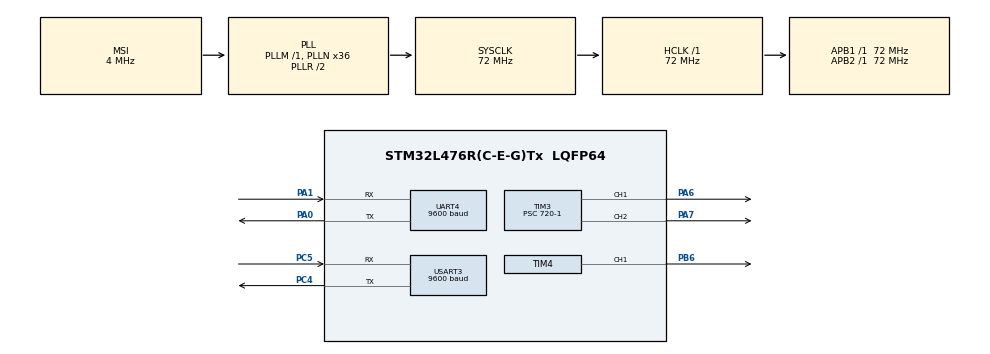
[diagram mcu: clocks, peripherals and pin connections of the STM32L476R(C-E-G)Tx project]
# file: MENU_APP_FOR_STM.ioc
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Mcu.Family=STM32L4
Mcu.Name=STM32L476R(C-E-G)Tx
Mcu.Package=LQFP64
NVIC.PriorityGroup=NVIC_PRIORITYGROUP_4
NVIC.TIM1_UP_TIM16_IRQn=true\:0\:0\:false\:false\:true\:true\:true\:true
NVIC.TIM3_IRQn=true\:0\:0\:false\:false\:true\:true\:true\:true
NVIC.TIM4_IRQn=true\:0\:0\:false\:false\:true\:true\:true\:true
NVIC.UART4_IRQn=true\:0\:0\:false\:false\:true\:true\:true\:true
NVIC.USART3_IRQn=true\:0\:0\:false\:false\:true\:true\:true\:true
PA0.Mode=Asynchronous
PA0.Signal=UART4_TX
PA1.Mode=Asynchronous
PA1.Signal=UART4_RX
PA6.Signal=S_TIM3_CH1
PA7.Signal=S_TIM3_CH2
PB6.Signal=S_TIM4_CH1
PC4.Mode=Asynchronous
PC4.Signal=USART3_TX
PC5.Mode=Asynchronous
PC5.Signal=USART3_RX
ProjectManager.HeapSize=0x200
ProjectManager.StackSize=0x400
ProjectManager.TargetToolchain=STM32CubeIDE
RCC.AHBFreq_Value=72000000
RCC.APB1Freq_Value=72000000
RCC.APB1TimFreq_Value=72000000
RCC.APB2Freq_Value=72000000
RCC.APB2TimFreq_Value=72000000
RCC.CortexFreq_Value=72000000
RCC.HCLKFreq_Value=72000000
RCC.HSE_VALUE=8000000
RCC.HSI_VALUE=16000000
RCC.LSE_VALUE=32768
RCC.MSI_VALUE=4000000
RCC.PLLN=36
RCC.SYSCLKFreq_VALUE=72000000
RCC.SYSCLKSource=RCC_SYSCLKSOURCE_PLLCLK
RCC.VCOOutputFreq_Value=144000000
SH.S_TIM3_CH1.0=TIM3_CH1,PWM Generation1 CH1
SH.S_TIM3_CH2.0=TIM3_CH2,PWM Generation2 CH2
SH.S_TIM4_CH1.0=TIM4_CH1,PWM Generation1 CH1
TIM16.Period=100-1
TIM16.Prescaler=720-1
TIM3.Channel-PWM\ Generation1\ CH1=TIM_CHANNEL_1
TIM3.Channel-PWM\ Generation2\ CH2=TIM_CHANNEL_2
TIM3.Period=200-1
TIM3.Prescaler=720-1
TIM4.Channel-PWM\ Generation1\ CH1=TIM_CHANNEL_1
TIM4.Period=200-1
TIM4.Prescaler=720-1
UART4.BaudRate=9600
USART3.BaudRate=9600
USART3.VirtualMode-Asynchronous=VM_ASYNC
VP_TIM16_VS_ClockSourceINT.Mode=Enable_Timer
board=custom

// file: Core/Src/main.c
/* USER CODE BEGIN Header */
/**
  ******************************************************************************
  * @file           : main.c
  * @author			: Matheus Gouveia
  * @brief   		: A Menu application for STM32L746RG
  *
  ******************************************************************************
  * @attention
  *
  * <h2><center>&copy; Copyright (c) 2022 STMicroelectronics.
  * All rights reserved.</center></h2>
  *
  * This software component is licensed by ST under BSD 3-Clause license,
  * the "License"; You may not use this file except in compliance with the
  * License. You may obtain a copy of the License at:
  *                        opensource.org/licenses/BSD-3-Clause
  *
  *
  *  Created on: 30/08/2022
  *
  *
  ******************************************************************************
  */
/* USER CODE END Header */
#include "main.h"

/* USER CODE BEGIN Includes */

#include "string.h"
#include <stdio.h>
#include <stdlib.h>
#include <sys_definitions.h>
#include <Menu_user.h>

/* USER CODE END Includes */

void SystemClock_Config(void);
static void MX_GPIO_Init(void);
static void MX_TIM3_Init(void);
static void MX_TIM4_Init(void);
static void MX_TIM16_Init(void);
static void MX_UART4_Init(void);
static void MX_USART3_UART_Init(void);

/* USER CODE BEGIN 0 */

////////////////////////////////////////////////////////////////////////////////

/**------------------------------------------------------------------------------------
  * @brief Funcao callback para dados recebidos do radio.
  *
  * @OBS Interrupcao UART 3. Apos start byte preenche buffer,
  * 	 parando quando recebe o end byte. Apos buffer completo,
  * 	 verifica a mensagem.
  *
  * @param  *huart:		Objeto UART.
  *
  * @retval void
  */
void HAL_UART_RxCpltCallback(UART_HandleTypeDef *huart){

	/* LED indicator data received. */
	//HAL_GPIO_WritePin(LED_GREEN_GPIO_Port, LED_GREEN_Pin, HIGH);

	/* index data packet */
	static int cont_index = 0;
	/* Enable buffer fill after start byte */
	static int enable_fill_buffer = 0;

	//if (Data[0] == end_byte[0]) {
	//	cont_index = 0;
	//	enable_fill_buffer = 0;

		//put some application here;
	//}
	//else {
	//	if (Data[0] == start_byte[0]){
	//		enable_fill_buffer = 1;
	//	}
	//	else if (enable_fill_buffer){
	//		BUFFER_RECEIVE[cont_index] = Data[0];
	//		cont_index++;
	//	}
	//}
	//HAL_UART_Receive_IT(&huart3, Data, 1);
}

/**------------------------------------------------------------------------------------
  * @brief Funcao callback quando dados forem enviados.
  *
  * @OBS Interrupcao UART 3.
  *
  * @param  *huart:		Objeto UART.
  *
  * @retval void
  */
void HAL_UART_TxCpltCallback(UART_HandleTypeDef *huart){

	if (huart == &huart3){
		/* Acender LED de dado Serial enviado */
		//HAL_GPIO_WritePin(LED_RED_GPIO_Port, LED_RED_Pin, HIGH);
	}

}

/* USER CODE END 0 */

int main(void)
{

  /* MCU Configuration--------------------------------------------------------*/

  /* Reset of all peripherals, Initializes the Flash interface and the Systick. */
  HAL_Init();

  /* Configure the system clock */
  SystemClock_Config();

  /* Initialize all configured peripherals */
  MX_GPIO_Init();
  MX_TIM3_Init();
  MX_TIM4_Init();
  MX_TIM16_Init();
  MX_UART4_Init();
  MX_USART3_UART_Init();

  /* Infinite loop */
  /* USER CODE BEGIN WHILE */
  while (1)
  {
	/* Wait for user data */
	Handle_user(100 /*time ms*/);
    /* USER CODE END WHILE */

  }
}

void SystemClock_Config(void)
{
  RCC_OscInitTypeDef RCC_OscInitStruct = {0};
  RCC_ClkInitTypeDef RCC_ClkInitStruct = {0};

  /** Configure the main internal regulator output voltage
  */
  if (HAL_PWREx_ControlVoltageScaling(PWR_REGULATOR_VOLTAGE_SCALE1) != HAL_OK)
  {
    Error_Handler();
  }

  /** Initializes the RCC Oscillators according to the specified parameters
  * in the RCC_OscInitTypeDef structure.
  */
  RCC_OscInitStruct.OscillatorType = RCC_OSCILLATORTYPE_MSI;
  RCC_OscInitStruct.MSIState = RCC_MSI_ON;
  RCC_OscInitStruct.MSICalibrationValue = 0;
  RCC_OscInitStruct.MSIClockRange = RCC_MSIRANGE_6;
  RCC_OscInitStruct.PLL.PLLState = RCC_PLL_ON;
  RCC_OscInitStruct.PLL.PLLSource = RCC_PLLSOURCE_MSI;
  RCC_OscInitStruct.PLL.PLLM = 1;
  RCC_OscInitStruct.PLL.PLLN = 36;
  RCC_OscInitStruct.PLL.PLLP = RCC_PLLP_DIV7;
  RCC_OscInitStruct.PLL.PLLQ = RCC_PLLQ_DIV2;
  RCC_OscInitStruct.PLL.PLLR = RCC_PLLR_DIV2;
  if (HAL_RCC_OscConfig(&RCC_OscInitStruct) != HAL_OK)
  {
    Error_Handler();
  }

  /** Initializes the CPU, AHB and APB buses clocks
  */
  RCC_ClkInitStruct.ClockType = RCC_CLOCKTYPE_HCLK|RCC_CLOCKTYPE_SYSCLK
                              |RCC_CLOCKTYPE_PCLK1|RCC_CLOCKTYPE_PCLK2;
  RCC_ClkInitStruct.SYSCLKSource = RCC_SYSCLKSOURCE_PLLCLK;
  RCC_ClkInitStruct.AHBCLKDivider = RCC_SYSCLK_DIV1;
  RCC_ClkInitStruct.APB1CLKDivider = RCC_HCLK_DIV1;
  RCC_ClkInitStruct.APB2CLKDivider = RCC_HCLK_DIV1;

  if (HAL_RCC_ClockConfig(&RCC_ClkInitStruct, FLASH_LATENCY_4) != HAL_OK)
  {
    Error_Handler();
  }
}

static void MX_TIM3_Init(void)
{

  TIM_MasterConfigTypeDef sMasterConfig = {0};
  TIM_OC_InitTypeDef sConfigOC = {0};

  htim3.Instance = TIM3;
  htim3.Init.Prescaler = 720-1;
  htim3.Init.CounterMode = TIM_COUNTERMODE_UP;
  htim3.Init.Period = 200-1;
  htim3.Init.ClockDivision = TIM_CLOCKDIVISION_DIV1;
  htim3.Init.AutoReloadPreload = TIM_AUTORELOAD_PRELOAD_DISABLE;
  if (HAL_TIM_PWM_Init(&htim3) != HAL_OK)
  {
    Error_Handler();
  }
  sMasterConfig.MasterOutputTrigger = TIM_TRGO_RESET;
  sMasterConfig.MasterSlaveMode = TIM_MASTERSLAVEMODE_DISABLE;
  if (HAL_TIMEx_MasterConfigSynchronization(&htim3, &sMasterConfig) != HAL_OK)
  {
    Error_Handler();
  }
  sConfigOC.OCMode = TIM_OCMODE_PWM1;
  sConfigOC.Pulse = 0;
  sConfigOC.OCPolarity = TIM_OCPOLARITY_HIGH;
  sConfigOC.OCFastMode = TIM_OCFAST_DISABLE;
  if (HAL_TIM_PWM_ConfigChannel(&htim3, &sConfigOC, TIM_CHANNEL_1) != HAL_OK)
  {
    Error_Handler();
  }
  if (HAL_TIM_PWM_ConfigChannel(&htim3, &sConfigOC, TIM_CHANNEL_2) != HAL_OK)
  {
    Error_Handler();
  }
  HAL_TIM_MspPostInit(&htim3);

}

static void MX_TIM4_Init(void)
{

  TIM_MasterConfigTypeDef sMasterConfig = {0};
  TIM_OC_InitTypeDef sConfigOC = {0};

  htim4.Instance = TIM4;
  htim4.Init.Prescaler = 720-1;
  htim4.Init.CounterMode = TIM_COUNTERMODE_UP;
  htim4.Init.Period = 200-1;
  htim4.Init.ClockDivision = TIM_CLOCKDIVISION_DIV1;
  htim4.Init.AutoReloadPreload = TIM_AUTORELOAD_PRELOAD_DISABLE;
  if (HAL_TIM_PWM_Init(&htim4) != HAL_OK)
  {
    Error_Handler();
  }
  sMasterConfig.MasterOutputTrigger = TIM_TRGO_RESET;
  sMasterConfig.MasterSlaveMode = TIM_MASTERSLAVEMODE_DISABLE;
  if (HAL_TIMEx_MasterConfigSynchronization(&htim4, &sMasterConfig) != HAL_OK)
  {
    Error_Handler();
  }
  sConfigOC.OCMode = TIM_OCMODE_PWM1;
  sConfigOC.Pulse = 0;
  sConfigOC.OCPolarity = TIM_OCPOLARITY_HIGH;
  sConfigOC.OCFastMode = TIM_OCFAST_DISABLE;
  if (HAL_TIM_PWM_ConfigChannel(&htim4, &sConfigOC, TIM_CHANNEL_1) != HAL_OK)
  {
    Error_Handler();
  }
  HAL_TIM_MspPostInit(&htim4);

}

static void MX_TIM16_Init(void)
{

  htim16.Instance = TIM16;
  htim16.Init.Prescaler = 720-1;
  htim16.Init.CounterMode = TIM_COUNTERMODE_UP;
  htim16.Init.Period = 100-1;
  htim16.Init.ClockDivision = TIM_CLOCKDIVISION_DIV1;
  htim16.Init.RepetitionCounter = 0;
  htim16.Init.AutoReloadPreload = TIM_AUTORELOAD_PRELOAD_DISABLE;
  if (HAL_TIM_Base_Init(&htim16) != HAL_OK)
  {
    Error_Handler();
  }

}

static void MX_UART4_Init(void)
{

  huart4.Instance = UART4;
  huart4.Init.BaudRate = 9600;
  huart4.Init.WordLength = UART_WORDLENGTH_8B;
  huart4.Init.StopBits = UART_STOPBITS_1;
  huart4.Init.Parity = UART_PARITY_NONE;
  huart4.Init.Mode = UART_MODE_TX_RX;
  huart4.Init.HwFlowCtl = UART_HWCONTROL_NONE;
  huart4.Init.OverSampling = UART_OVERSAMPLING_16;
  huart4.Init.OneBitSampling = UART_ONE_BIT_SAMPLE_DISABLE;
  huart4.AdvancedInit.AdvFeatureInit = UART_ADVFEATURE_NO_INIT;
  if (HAL_UART_Init(&huart4) != HAL_OK)
  {
    Error_Handler();
  }

}

static void MX_USART3_UART_Init(void)
{

  huart3.Instance = USART3;
  huart3.Init.BaudRate = 9600;
  huart3.Init.WordLength = UART_WORDLENGTH_8B;
  huart3.Init.StopBits = UART_STOPBITS_1;
  huart3.Init.Parity = UART_PARITY_NONE;
  huart3.Init.Mode = UART_MODE_TX_RX;
  huart3.Init.HwFlowCtl = UART_HWCONTROL_NONE;
  huart3.Init.OverSampling = UART_OVERSAMPLING_16;
  huart3.Init.OneBitSampling = UART_ONE_BIT_SAMPLE_DISABLE;
  huart3.AdvancedInit.AdvFeatureInit = UART_ADVFEATURE_NO_INIT;
  if (HAL_UART_Init(&huart3) != HAL_OK)
  {
    Error_Handler();
  }

}

static void MX_GPIO_Init(void)
{

  /* GPIO Ports Clock Enable */
  __HAL_RCC_GPIOA_CLK_ENABLE();
  __HAL_RCC_GPIOC_CLK_ENABLE();
  __HAL_RCC_GPIOB_CLK_ENABLE();

}

void Error_Handler(void)
{
  __disable_irq();
  while (1)
  {
  }
}
